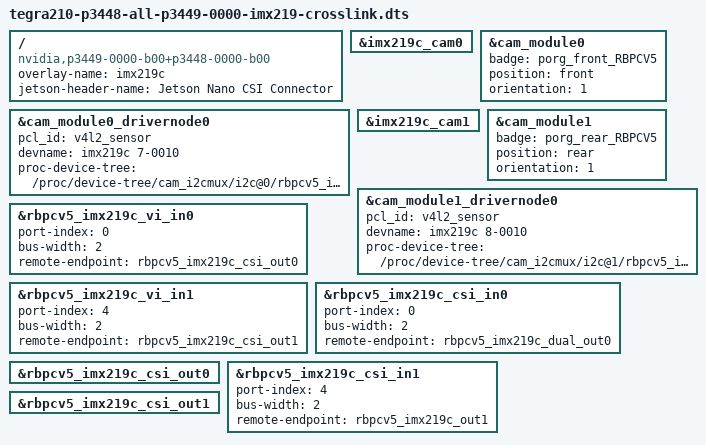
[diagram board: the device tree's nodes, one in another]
// SPDX-License-Identifier: GPL-2.0-only
/*
 * Jetson Device-tree overlay for IMX219 Crosslink rbpcv5 for t210 single
 * cam connector baseboards
 *
 * Copyright (c) 2021 NVIDIA CORPORATION. All rights reserved.
 *
 */

/dts-v1/;
/plugin/;

/ {
	overlay-name = "imx219c";
	jetson-header-name = "Jetson Nano CSI Connector";
	compatible = "nvidia,p3449-0000-b00+p3448-0000-b00", "nvidia,p3449-0000-b00+p3448-0002-b00";

	/* IM219 Crosslink dual sensor module */
	fragment@0 {
		target = <&imx219c_cam0>;
		__overlay__ {
			status = "okay";
		};
	};
	fragment@1 {
		target = <&cam_module0>;
		__overlay__ {
			status = "okay";
			badge = "porg_front_RBPCV5";
			position = "front";
			orientation = "1";
		};
	};
	fragment@2 {
		target = <&cam_module0_drivernode0>;
		__overlay__ {
			status = "okay";
			pcl_id = "v4l2_sensor";
			devname = "imx219c 7-0010";
			proc-device-tree = "/proc/device-tree/cam_i2cmux/i2c@0/rbpcv5_imx219c_a@10";
		};
	};
	fragment@3 {
		target = <&imx219c_cam1>;
		__overlay__ {
			status = "okay";
		};
	};
	fragment@4 {
		target = <&cam_module1>;
		__overlay__ {
			status = "okay";
			badge = "porg_rear_RBPCV5";
			position = "rear";
			orientation = "1";
		};
	};
	fragment@5 {
		target = <&cam_module1_drivernode0>;
		__overlay__ {
			status = "okay";
			pcl_id = "v4l2_sensor";
			devname = "imx219c 8-0010";
			proc-device-tree = "/proc/device-tree/cam_i2cmux/i2c@1/rbpcv5_imx219c_e@10";
		};
	};

	fragment@7 {
		target = <&rbpcv5_imx219c_vi_in0>;
		__overlay__ {
			status = "okay";
			port-index = <0>;
			bus-width = <2>;
			remote-endpoint = <&rbpcv5_imx219c_csi_out0>;
		};
	};
	fragment@8 {
		target = <&rbpcv5_imx219c_vi_in1>;
		__overlay__ {
			status = "okay";
			port-index = <4>;
			bus-width = <2>;
			remote-endpoint = <&rbpcv5_imx219c_csi_out1>;
		};
	};
	fragment@9 {
		target = <&rbpcv5_imx219c_csi_in0>;
		__overlay__ {
			status = "okay";
			port-index = <0>;
			bus-width = <2>;
			remote-endpoint = <&rbpcv5_imx219c_dual_out0>;
		};
	};
	fragment@10 {
		target = <&rbpcv5_imx219c_csi_out0>;
		__overlay__ {
			status = "okay";
		};
	};
	fragment@11 {
		target = <&rbpcv5_imx219c_csi_in1>;
		__overlay__ {
			status = "okay";
			port-index = <4>;
			bus-width = <2>;
			remote-endpoint = <&rbpcv5_imx219c_out1>;
		};
	};
	fragment@12 {
		target = <&rbpcv5_imx219c_csi_out1>;
		__overlay__ {
			status = "okay";
		};
	};

/*
	fragment@6 {
		target = <&imx219_cam0>;
		__overlay__ {
			status = "disabled";
		};
	};
	fragment@13 {
		target = <&imx219_cam1>;
		__overlay__ {
			status = "disabled";
		};
	};
*/

};
